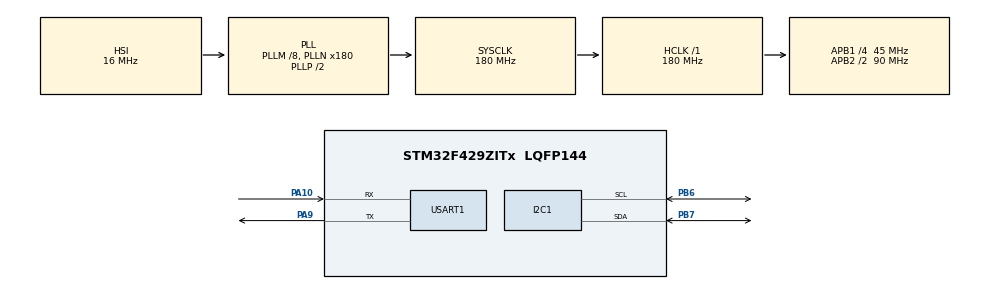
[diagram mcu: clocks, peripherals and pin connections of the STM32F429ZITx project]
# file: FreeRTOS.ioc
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FREERTOS.BinarySemaphores01=BinSem,Dynamic,NULL
FREERTOS.Tasks01=Task1,3,128,StartTask1,Default,NULL,Dynamic,NULL,NULL;Task02,2,128,StartTask02,Default,NULL,Dynamic,NULL,NULL
Mcu.Family=STM32F4
Mcu.Name=STM32F429ZITx
Mcu.Package=LQFP144
NVIC.PriorityGroup=NVIC_PRIORITYGROUP_4
NVIC.TIM1_UP_TIM10_IRQn=true\:0\:0\:false\:false\:true\:false\:false\:true
NVIC.TimeBase=TIM1_UP_TIM10_IRQn
NVIC.TimeBaseIP=TIM1
PA10.Mode=Asynchronous
PA10.Signal=USART1_RX
PA9.Mode=Asynchronous
PA9.Signal=USART1_TX
PB6.Mode=I2C
PB6.Signal=I2C1_SCL
PB7.Mode=I2C
PB7.Signal=I2C1_SDA
PH0/OSC_IN.Mode=HSE-External-Oscillator
PH0/OSC_IN.Signal=RCC_OSC_IN
PH1/OSC_OUT.Mode=HSE-External-Oscillator
PH1/OSC_OUT.Signal=RCC_OSC_OUT
ProjectManager.HeapSize=0x200
ProjectManager.StackSize=0x400
ProjectManager.TargetToolchain=STM32CubeIDE
RCC.48MHZClocksFreq_Value=90000000
RCC.AHBFreq_Value=180000000
RCC.APB1CLKDivider=RCC_HCLK_DIV4
RCC.APB1Freq_Value=45000000
RCC.APB1TimFreq_Value=90000000
RCC.APB2CLKDivider=RCC_HCLK_DIV2
RCC.APB2Freq_Value=90000000
RCC.APB2TimFreq_Value=180000000
RCC.CortexFreq_Value=180000000
RCC.HCLKFreq_Value=180000000
RCC.HSE_VALUE=8000000
RCC.HSI_VALUE=16000000
RCC.LSE_VALUE=32768
RCC.PLLM=8
RCC.PLLN=180
RCC.SYSCLKFreq_VALUE=180000000
RCC.SYSCLKSource=RCC_SYSCLKSOURCE_PLLCLK
RCC.VCOOutputFreq_Value=360000000
USART1.VirtualMode=VM_ASYNC
VP_FREERTOS_VS_CMSIS_V1.Mode=CMSIS_V1
VP_SYS_VS_tim1.Mode=TIM1
board=custom

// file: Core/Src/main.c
/* USER CODE BEGIN Header */
/**
  ******************************************************************************
  * @file           : main.c
  * @brief          : Main program body
  ******************************************************************************
  * @attention
  *
  * <h2><center>&copy; Copyright (c) 2021 STMicroelectronics.
  * All rights reserved.</center></h2>
  *
  * This software component is licensed by ST under BSD 3-Clause license,
  * the "License"; You may not use this file except in compliance with the
  * License. You may obtain a copy of the License at:
  *                        opensource.org/licenses/BSD-3-Clause
  *
  ******************************************************************************
  */
/* USER CODE END Header */
#include "main.h"
#include "cmsis_os.h"

/* USER CODE BEGIN Includes */
#include "MPU6050.h"
/* USER CODE END Includes */

I2C_HandleTypeDef hi2c1;

UART_HandleTypeDef huart1;

osThreadId Task1Handle;
osThreadId Task02Handle;
osSemaphoreId BinSemHandle;
/* USER CODE BEGIN PV */
MPU6050_Gyro Gyro;
/* USER CODE END PV */

void SystemClock_Config(void);
static void MX_GPIO_Init(void);
static void MX_I2C1_Init(void);
static void MX_USART1_UART_Init(void);
void StartTask1(void const * argument);
void StartTask02(void const * argument);

/* USER CODE BEGIN 0 */
PUTCHAR_PROTOTYPE{
		HAL_UART_Transmit(&huart1, (uint8_t *)&ch, 1, 0xFFFF);
		return ch;
}
/* USER CODE END 0 */

int main(void)
{

  /* MCU Configuration--------------------------------------------------------*/

  /* Reset of all peripherals, Initializes the Flash interface and the Systick. */
  HAL_Init();

  /* USER CODE BEGIN Init */
  MPU6050_Init();
  /* USER CODE END Init */

  /* Configure the system clock */
  SystemClock_Config();

  /* Initialize all configured peripherals */
  MX_GPIO_Init();
  MX_I2C1_Init();
  MX_USART1_UART_Init();

  /* Create the semaphores(s) */
  /* definition and creation of BinSem */
  osSemaphoreDef(BinSem);
  BinSemHandle = osSemaphoreCreate(osSemaphore(BinSem), 1);

  /* Create the thread(s) */
  /* definition and creation of Task1 */
  osThreadDef(Task1, StartTask1, osPriorityRealtime, 0, 128*4);
  Task1Handle = osThreadCreate(osThread(Task1), NULL);

  /* definition and creation of Task02 */
  osThreadDef(Task02, StartTask02, osPriorityHigh, 0, 128*4);
  Task02Handle = osThreadCreate(osThread(Task02), NULL);

  /* Start scheduler */
  osKernelStart();

  /* We should never get here as control is now taken by the scheduler */
  /* Infinite loop */
  while (1)
  {

  }
}

void SystemClock_Config(void)
{
  RCC_OscInitTypeDef RCC_OscInitStruct = {0};
  RCC_ClkInitTypeDef RCC_ClkInitStruct = {0};

  /** Configure the main internal regulator output voltage
  */
  __HAL_RCC_PWR_CLK_ENABLE();
  __HAL_PWR_VOLTAGESCALING_CONFIG(PWR_REGULATOR_VOLTAGE_SCALE1);
  /** Initializes the RCC Oscillators according to the specified parameters
  * in the RCC_OscInitTypeDef structure.
  */
  RCC_OscInitStruct.OscillatorType = RCC_OSCILLATORTYPE_HSI;
  RCC_OscInitStruct.HSIState = RCC_HSI_ON;
  RCC_OscInitStruct.HSICalibrationValue = RCC_HSICALIBRATION_DEFAULT;
  RCC_OscInitStruct.PLL.PLLState = RCC_PLL_ON;
  RCC_OscInitStruct.PLL.PLLSource = RCC_PLLSOURCE_HSI;
  RCC_OscInitStruct.PLL.PLLM = 8;
  RCC_OscInitStruct.PLL.PLLN = 180;
  RCC_OscInitStruct.PLL.PLLP = RCC_PLLP_DIV2;
  RCC_OscInitStruct.PLL.PLLQ = 4;
  if (HAL_RCC_OscConfig(&RCC_OscInitStruct) != HAL_OK)
  {
    Error_Handler();
  }
  /** Activate the Over-Drive mode
  */
  if (HAL_PWREx_EnableOverDrive() != HAL_OK)
  {
    Error_Handler();
  }
  /** Initializes the CPU, AHB and APB buses clocks
  */
  RCC_ClkInitStruct.ClockType = RCC_CLOCKTYPE_HCLK|RCC_CLOCKTYPE_SYSCLK
                              |RCC_CLOCKTYPE_PCLK1|RCC_CLOCKTYPE_PCLK2;
  RCC_ClkInitStruct.SYSCLKSource = RCC_SYSCLKSOURCE_PLLCLK;
  RCC_ClkInitStruct.AHBCLKDivider = RCC_SYSCLK_DIV1;
  RCC_ClkInitStruct.APB1CLKDivider = RCC_HCLK_DIV4;
  RCC_ClkInitStruct.APB2CLKDivider = RCC_HCLK_DIV2;

  if (HAL_RCC_ClockConfig(&RCC_ClkInitStruct, FLASH_LATENCY_5) != HAL_OK)
  {
    Error_Handler();
  }
}

static void MX_I2C1_Init(void)
{

  hi2c1.Instance = I2C1;
  hi2c1.Init.ClockSpeed = 100000;
  hi2c1.Init.DutyCycle = I2C_DUTYCYCLE_2;
  hi2c1.Init.OwnAddress1 = 0;
  hi2c1.Init.AddressingMode = I2C_ADDRESSINGMODE_7BIT;
  hi2c1.Init.DualAddressMode = I2C_DUALADDRESS_DISABLE;
  hi2c1.Init.OwnAddress2 = 0;
  hi2c1.Init.GeneralCallMode = I2C_GENERALCALL_DISABLE;
  hi2c1.Init.NoStretchMode = I2C_NOSTRETCH_DISABLE;
  if (HAL_I2C_Init(&hi2c1) != HAL_OK)
  {
    Error_Handler();
  }
  /** Configure Analogue filter
  */
  if (HAL_I2CEx_ConfigAnalogFilter(&hi2c1, I2C_ANALOGFILTER_ENABLE) != HAL_OK)
  {
    Error_Handler();
  }
  /** Configure Digital filter
  */
  if (HAL_I2CEx_ConfigDigitalFilter(&hi2c1, 0) != HAL_OK)
  {
    Error_Handler();
  }

}

static void MX_USART1_UART_Init(void)
{

  huart1.Instance = USART1;
  huart1.Init.BaudRate = 115200;
  huart1.Init.WordLength = UART_WORDLENGTH_8B;
  huart1.Init.StopBits = UART_STOPBITS_1;
  huart1.Init.Parity = UART_PARITY_NONE;
  huart1.Init.Mode = UART_MODE_TX_RX;
  huart1.Init.HwFlowCtl = UART_HWCONTROL_NONE;
  huart1.Init.OverSampling = UART_OVERSAMPLING_16;
  if (HAL_UART_Init(&huart1) != HAL_OK)
  {
    Error_Handler();
  }

}

static void MX_GPIO_Init(void)
{

  /* GPIO Ports Clock Enable */
  __HAL_RCC_GPIOH_CLK_ENABLE();
  __HAL_RCC_GPIOA_CLK_ENABLE();
  __HAL_RCC_GPIOB_CLK_ENABLE();

}

void StartTask1(void const * argument)
{
  /* USER CODE BEGIN 5 */
  /* Infinite loop */
  for(;;)
  {
	osSemaphoreWait(BinSemHandle, osWaitForever);
	MPU6050_Read_Gyro(&Gyro);
	osSemaphoreRelease(BinSemHandle);
//	printf("hhaha \n");
    osDelay(100);
  }
  /* USER CODE END 5 */
}

void StartTask02(void const * argument)
{
  /* USER CODE BEGIN StartTask02 */
  /* Infinite loop */
  for(;;)
  {
	osSemaphoreWait(BinSemHandle, osWaitForever);
	printf("Gyroscope value: x = %f , y = %f , z = %f \n",Gyro.x,Gyro.y,Gyro.z);
//	printf("Hello \n");
//	osThreadTerminate(Task02Handle);
	osSemaphoreRelease(BinSemHandle);
	osDelay(100);
  }
  /* USER CODE END StartTask02 */
}

 /**
  * @brief  Period elapsed callback in non blocking mode
  * @note   This function is called  when TIM1 interrupt took place, inside
  * HAL_TIM_IRQHandler(). It makes a direct call to HAL_IncTick() to increment
  * a global variable "uwTick" used as application time base.
  * @param  htim : TIM handle
  * @retval None
  */
void HAL_TIM_PeriodElapsedCallback(TIM_HandleTypeDef *htim)
{
  if (htim->Instance == TIM1) {
    HAL_IncTick();
  }
}

void Error_Handler(void)
{
  __disable_irq();
  while (1)
  {
  }
}

/************************ (C) COPYRIGHT STMicroelectronics *****END OF FILE****/
